# WLR089U0 register map
Vendor: Microchip
Registers are 32-bit, read-write, reset 0x0 unless marked. A register's access mark holds for its fields unless they carry their own. Addresses are absolute, and some are shared; only a register's first bit layout is shown; [hi:lo] are bit positions; 'fields as' and 'values as' point back to an identical list; <NAME> marks a mode.

## TC3
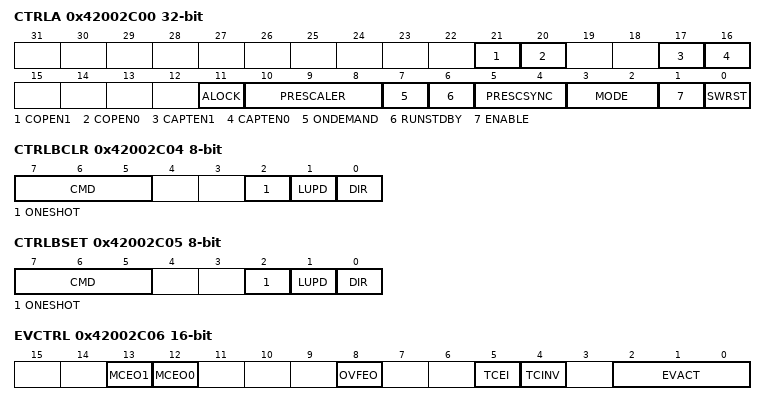
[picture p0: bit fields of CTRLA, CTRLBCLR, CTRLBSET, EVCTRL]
0x42002C00 CTRLA
  [21] COPEN1 — Capture On Pin 1 Enable
  [20] COPEN0 — Capture On Pin 0 Enable
  [17] CAPTEN1 — Capture Channel 1 Enable
  [16] CAPTEN0 — Capture Channel 0 Enable
  [11] ALOCK — Auto Lock
  [10:8] PRESCALER
    0=DIV1 (Prescaler: GCLK_TC); 1=DIV2 (Prescaler: GCLK_TC/2); 2=DIV4 (Prescaler: GCLK_TC/4); 3=DIV8 (Prescaler: GCLK_TC/8); 4=DIV16 (Prescaler: GCLK_TC/16); 5=DIV64 (Prescaler: GCLK_TC/64); 6=DIV256 (Prescaler: GCLK_TC/256); 7=DIV1024 (Prescaler: GCLK_TC/1024)
  [7] ONDEMAND — Clock On Demand
  [6] RUNSTDBY — Run during Standby
  [5:4] PRESCSYNC — Prescaler and Counter Synchronization
    0=GCLK (Reload or reset the counter on next generic clock); 1=PRESC (Reload or reset the counter on next prescaler clock); 2=RESYNC (Reload or reset the counter on next generic clock and reset the prescaler counter)
  [3:2] MODE — Timer Counter Mode
    0=COUNT16 (Counter in 16-bit mode); 1=COUNT8 (Counter in 8-bit mode); 2=COUNT32 (Counter in 32-bit mode)
  [1] ENABLE
  [0] SWRST — Software Reset
0x42002C04 CTRLBCLR 8-bit
  [7:5] CMD — Command
    0=NONE (No action); 1=RETRIGGER (Force a start, restart or retrigger); 2=STOP (Force a stop); 3=UPDATE (Force update of double-buffered register); 4=READSYNC (Force a read synchronization of COUNT); 5=DMAOS (One-shot DMA trigger)
  [2] ONESHOT — One-Shot on Counter
  [1] LUPD — Lock Update
  [0] DIR — Counter Direction
0x42002C05 CTRLBSET 8-bit
  fields as CTRLBCLR
0x42002C06 EVCTRL 16-bit
  [13] MCEO1 — MC Event Output Enable 1
  [12] MCEO0 — MC Event Output Enable 0
  [8] OVFEO — Event Output Enable
  [5] TCEI — TC Event Enable
  [4] TCINV — TC Event Input Polarity
  [2:0] EVACT — Event Action
    0=OFF (Event action disabled); 1=RETRIGGER (Start, restart or retrigger TC on event); 2=COUNT (Count on event); 3=START (Start TC on event); 4=STAMP (Time stamp capture); 5=PPW (Period captured in CC0, pulse width in CC1); 6=PWP (Period captured in CC1, pulse width in CC0); 7=PW (Pulse width capture)
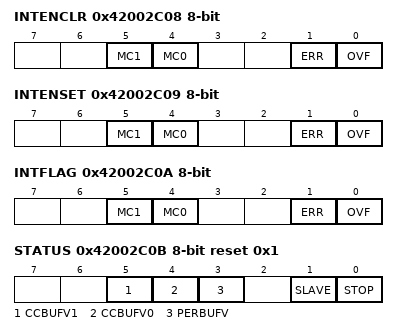
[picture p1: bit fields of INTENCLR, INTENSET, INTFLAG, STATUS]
0x42002C08 INTENCLR 8-bit
  [5] MC1 — MC Interrupt Disable 1
  [4] MC0 — MC Interrupt Disable 0
  [1] ERR — ERR Interrupt Disable
  [0] OVF — OVF Interrupt Disable
0x42002C09 INTENSET 8-bit
  [5] MC1 — MC Interrupt Enable 1
  [4] MC0 — MC Interrupt Enable 0
  [1] ERR — ERR Interrupt Enable
  [0] OVF — OVF Interrupt Enable
0x42002C0A INTFLAG 8-bit
  [5] MC1 — MC Interrupt Flag 1
  [4] MC0 — MC Interrupt Flag 0
  [1] ERR — ERR Interrupt Flag
  [0] OVF — OVF Interrupt Flag
0x42002C0B STATUS 8-bit reset 0x1
  [5] CCBUFV1 — Compare channel buffer 1 valid
  [4] CCBUFV0 — Compare channel buffer 0 valid
  [3] PERBUFV — Synchronization Busy Status
  [1] SLAVE — Slave Status Flag
  [0] STOP — Stop Status Flag
0x42002C0C WAVE 8-bit
  [1:0] WAVEGEN — Waveform Generation Mode
    0=NFRQ (Normal frequency); 1=MFRQ (Match frequency); 2=NPWM (Normal PWM); 3=MPWM (Match PWM)
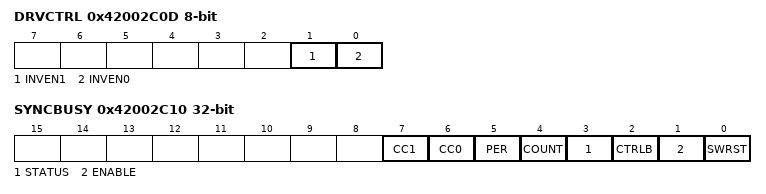
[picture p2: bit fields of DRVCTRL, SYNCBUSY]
0x42002C0D DRVCTRL 8-bit
  [1] INVEN1 — Output Waveform Invert Enable 1
  [0] INVEN0 — Output Waveform Invert Enable 0
0x42002C0F DBGCTRL 8-bit
  [0] DBGRUN — Run During Debug
0x42002C10 SYNCBUSY ro
  [7] CC1 — Compare Channel 1
  [6] CC0 — Compare Channel 0
  [5] PER — Period
  [4] COUNT — Counter
  [3] STATUS
  [2] CTRLB
  [1] ENABLE
  [0] SWRST

## DAC
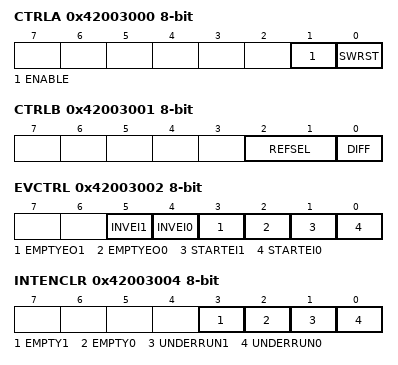
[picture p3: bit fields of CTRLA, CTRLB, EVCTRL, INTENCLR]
0x42003000 CTRLA 8-bit
  [1] ENABLE — Enable DAC Controller
  [0] SWRST — Software Reset
0x42003001 CTRLB 8-bit
  [2:1] REFSEL — Reference Selection for DAC0/1
    0=VREFPU (External reference unbuffered); 1=VDDANA (Analog supply); 2=VREFPB (External reference buffered); 3=INTREF (Internal bandgap reference)
  [0] DIFF — Differential mode enable
0x42003002 EVCTRL 8-bit
  [5] INVEI1 — Enable Invertion of DAC 1 input event
  [4] INVEI0 — Enable Invertion of DAC 0 input event
  [3] EMPTYEO1 — Data Buffer Empty Event Output DAC 1
  [2] EMPTYEO0 — Data Buffer Empty Event Output DAC 0
  [1] STARTEI1 — Start Conversion Event Input DAC 1
  [0] STARTEI0 — Start Conversion Event Input DAC 0
0x42003004 INTENCLR 8-bit
  [3] EMPTY1 — Data Buffer 1 Empty Interrupt Enable
  [2] EMPTY0 — Data Buffer 0 Empty Interrupt Enable
  [1] UNDERRUN1 — Underrun Interrupt Enable for DAC 1
  [0] UNDERRUN0 — Underrun Interrupt Enable for DAC 0
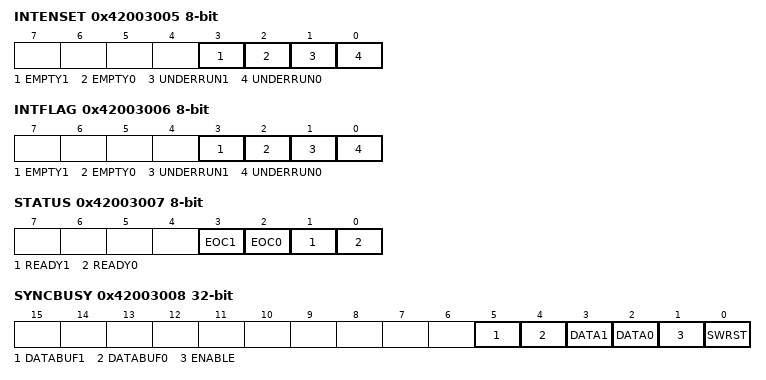
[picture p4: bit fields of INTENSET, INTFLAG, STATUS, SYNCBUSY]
0x42003005 INTENSET 8-bit
  fields as INTENCLR
0x42003006 INTFLAG 8-bit
  [3] EMPTY1 — Data Buffer 1 Empty
  [2] EMPTY0 — Data Buffer 0 Empty
  [1] UNDERRUN1 — DAC 1 Underrun
  [0] UNDERRUN0 — DAC 0 Underrun
0x42003007 STATUS 8-bit ro
  [3] EOC1 — DAC 1 End of Conversion
  [2] EOC0 — DAC 0 End of Conversion
  [1] READY1 — DAC 1 Startup Ready
  [0] READY0 — DAC 0 Startup Ready
0x42003008 SYNCBUSY ro
  [5] DATABUF1 — Data Buffer DAC 1
  [4] DATABUF0 — Data Buffer DAC 0
  [3] DATA1 — Data DAC 1
  [2] DATA0 — Data DAC 0
  [1] ENABLE — DAC Enable Status
  [0] SWRST — Software Reset
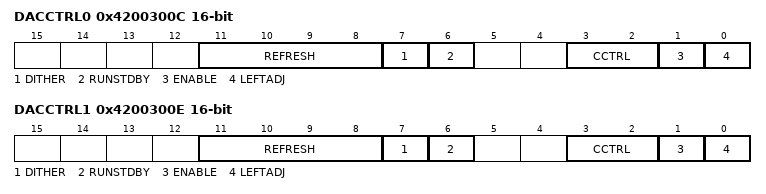
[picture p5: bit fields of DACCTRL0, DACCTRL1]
0x4200300C DACCTRL0 16-bit
  [11:8] REFRESH — Refresh period
    0=Do not Refresh; 2=Refresh every 60US; 3=Refresh every 90US; 4=Refresh every 120US; 5=Refresh every 150US; 6=Refresh every 180US; 7=Refresh every 210US; 8=Refresh every 240US; 9=Refresh every 270US; 10=Refresh every 300US; 11=Refresh every 330US; 12=Refresh every 360US; 13=Refresh every 390US; 14=Refresh every 420US; 15=Refresh every 450US
  [7] DITHER — Dithering Mode
  [6] RUNSTDBY — Run in Standby
  [3:2] CCTRL — Current Control
    0=CC100K (GCLK_DAC <= 1.2MHz (100kSPS)); 1=CC1M (1.2MHz < GCLK_DAC <= 6MHz (500kSPS)); 2=CC12M (6MHz < GCLK_DAC <=12MHz (1MSPS))
  [1] ENABLE — Enable DAC0
  [0] LEFTADJ — Left Adjusted Data
0x4200300E DACCTRL1 16-bit
  fields as DACCTRL0
0x42003010 DATA0 16-bit wo
  [15:0] DATA — DAC0 Data
0x42003012 DATA1 16-bit wo
  [15:0] DATA — DAC0 Data
0x42003014 DATABUF0 16-bit wo
  [15:0] DATABUF — DAC0 Data Buffer
0x42003016 DATABUF1 16-bit wo
  [15:0] DATABUF — DAC0 Data Buffer
0x42003018 DBGCTRL 8-bit
  [0] DBGRUN — Debug Run
